# DSI_Protocol_Engine register map
Vendor: Texas Instruments
Peripheral module from a debugger description file (folder omap36xx).
Registers are 32-bit, read-write, reset 0x0 unless marked. A register's access mark holds for its fields unless they carry their own. Offsets are as the file gives them; lines under a group give offsets from that group; [hi:lo] are bit positions; {n}, {i} and the like mark numbered series; 'fields as' and 'values as' point back to an identical list; <NAME> marks a mode.

## DSI_Protocol_Engine (part 1 of 2)
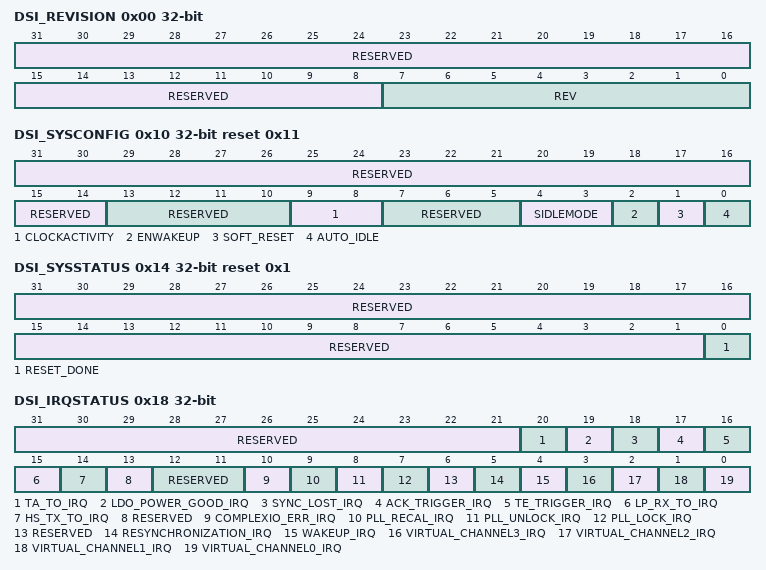
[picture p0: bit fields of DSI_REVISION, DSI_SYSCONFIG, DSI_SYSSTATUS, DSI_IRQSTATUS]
0x00 DSI_REVISION ro (reset mask 0xFFFFFF00) — MODULE REVISION This register contains the IP revision code in binary coded digital. For example, we have: 0x01 = revision 0.1 and 0x21 = revision 2.1
  [31:8] RESERVED — Write 0s for future compatibility.Reads returns 0.
  [7:0] REV — IP revision [7:4] Major revision[3:0] Minor revision
0x10 DSI_SYSCONFIG reset 0x11 — SYSTEM CONFIGURATION REGISTER This register is the system configuration register.
  [31:14] RESERVED — Write 0s for future compatibility.Reads returns 0.
  [13:10] RESERVED — Write 0s for future compatibility.
  [9:8] CLOCKACTIVITY — Clocks activity during wake up mode period
    0=Interface and Functional clocks can be switched off; 1=Functional clocks can be switched off and Interface clocks are maintained during wake up period; 2=Interface clocks can be switched off and Functional clocks are maintained during wake up period; 3=Interface and Functional clocks are maintained during wake up period
  [7:5] RESERVED — Write 0s for future compatibility.Reads returns 0.
  [4:3] SIDLEMODE — Slave interface power management, Idle req/ack control
    0=Force-idle. An idle request is acknowledged unconditionally; 1=No-idle. An idle request is never acknowledged; 2=Smart-idle. Acknowledgement to an idle request is given based on the internal activity of the module.
  [2] ENWAKEUP — Wake-up mode enable bit
    0=Wakeup is disabled; 1=Wakeup is enabled,
  [1] SOFT_RESET — Software reset. Set the bit to 1 to trigger a module reset. The bit is automatically reset by the hw. During reads return 0.
    0=Normal mode; 1=The module is reset
  [0] AUTO_IDLE — Internal interface clock gating strategy
    0=Interface clock is free-running; 1=Automatic Interface clock gating strategy is applied based on the module interface activity
0x14 DSI_SYSSTATUS ro reset 0x1 — SYSTEM STATUS REGISTER This register provides status information about the module, excluding the interrupt status register.
  [31:1] RESERVED — Reads returns 0.
  [0] RESET_DONE — Internal reset monitoring
    0=Internal module reset is on going; 1=Reset completed
0x18 DSI_IRQSTATUS access per field — INTERRUPT STATUS REGISTER - All VCs + complex I/O + PLL This register associates one bit for each VC to determine which VC has generated the interrupt. The VC should be enabled for events to be generated on that VC. If the VC is disabled, the interrupt is not generated.
  [31:21] RESERVED rw — Write 0s for future compatibility.Reads returns 0.
  [20] TA_TO_IRQ rw — Turn-around Time out.
    0=READS: Event is false.WRITES: Status bit unchanged; 1=READS: Event is true (pending).WRITES: Status bit is reset
  [19] LDO_POWER_GOOD_IRQ rw — Transition of the status signal LDOPWRGOOD from the DSI_PHY indicating a state change for the supply VDDALDODSIPLL from up to down or down to up.
    values as TA_TO_IRQ
  [18] SYNC_LOST_IRQ rw — Synchronization with Video port is lost (Video mode only)
    values as TA_TO_IRQ
  [17] ACK_TRIGGER_IRQ rw — Acknowledge Trigger
    values as TA_TO_IRQ
  [16] TE_TRIGGER_IRQ rw — Tearing Effect Trigger
    values as TA_TO_IRQ
  [15] LP_RX_TO_IRQ rw — Interrupt for Low Power Rx Time out
    values as TA_TO_IRQ
  [14] HS_TX_TO_IRQ rw — Interrupt for high-speed Tx Time out.
    values as TA_TO_IRQ
  [13] RESERVED rw — Write 0s for future compatibility.Reads returns 0.
  [12:11] RESERVED rw — Write 0s for future compatibility.Reads returns 0.
  [10] COMPLEXIO_ERR_IRQ ro — Error signaling from complex I/O: status of the complex I/O errors received from the complex I/O(events are defined inDSI_COMPLEXIO_IRQSTATUS).
    0=READS: Event is false; 1=READS: Event is true (pending)
  [9] PLL_RECAL_IRQ rw — PLL recalibration event (assertion of recalibration signal from the DSI PLL Control module)
    values as TA_TO_IRQ
  [8] PLL_UNLOCK_IRQ rw — PLL un-lock event (de-assertion of lock signal from the DSI PLL Control module)
    0=READS: Event is false.WRITES: Status bit unchanged; 1=READS: Event is true (pending). WRITES: Status bit is reset.
  [7] PLL_LOCK_IRQ rw — PLL lock event (assertion of lock signal from the DSI PLL Control module)
    values as TA_TO_IRQ
  [6] RESERVED rw — Write 0s for future compatibility.Reads returns 0.
  [5] RESYNCHRONIZATION_IRQ rw — Video mode resynchronizationIndicates that the video port works but the configuration of the timings for the display controller (DISPC) and for DSI protocol engine may have to be modified to avoid the resynchronization to occur. .
    0=READS: Event is false. WRITES: Status bit unchanged.; 1=READS: Event is true (pending). WRITES: Status bit is reset.
  [4] WAKEUP_IRQ rw — Wakeup
    values as TA_TO_IRQ
  [3] VIRTUAL_CHANNEL3_IRQ ro — Virtual channel #3Error signaling from DSI Virtual Channel3: Status of DSI Virtual Channel3 errors received from DSI Virtual Channel3 (events are defined in DSI_VC3_IRQSTATUS). .
    0=READS: Event is false; 1=READS: Event is true (pending)
  [2] VIRTUAL_CHANNEL2_IRQ ro — Virtual channel #2Error signaling from DSI Virtual Channel2: Status of DSI Virtual Channel2 errors received from DSI Virtual Channel2 (events are defined in DSI_VC2_IRQSTATUS). .
    0=READS: Event is false; 1=READS: Event is true (pending)
  [1] VIRTUAL_CHANNEL1_IRQ ro — Virtual channel #1Error signaling from DSI Virtual Channel1: Status of DSI Virtual Channel1 errors received from DSI Virtual Channel1 (events are defined in DSI_VC1_IRQSTATUS). .
    0=READS: Event is false; 1=READS: Event is true (pending)
  [0] VIRTUAL_CHANNEL0_IRQ ro — Virtual channel #0Error signaling from DSI Virtual Channel0: Status of the DSI Virtual Channel0 errors received from DSI Virtual Channel0 (events are defined in DSI_VC0_IRQSTATUS). .
    0=READS: Event is false; 1=READS: Event is true (pending)
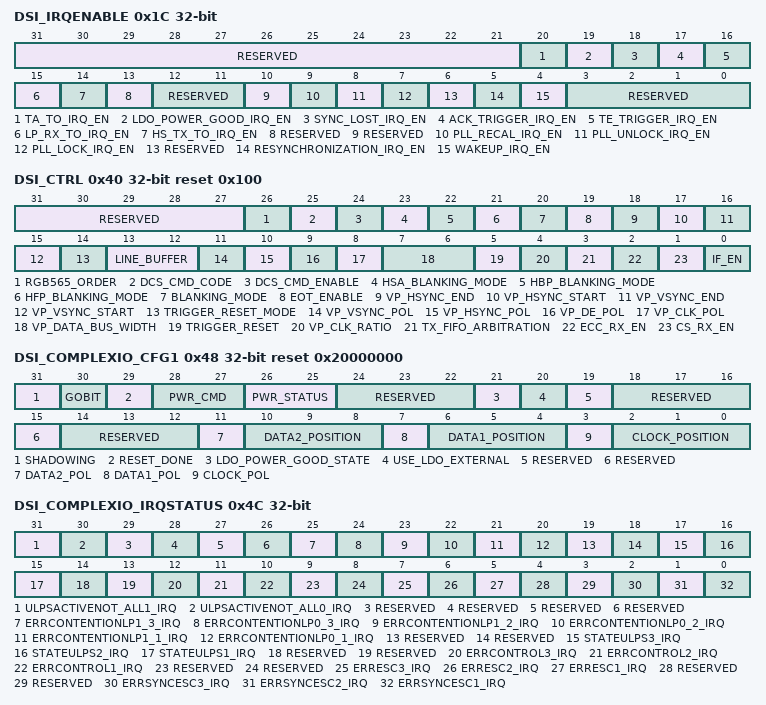
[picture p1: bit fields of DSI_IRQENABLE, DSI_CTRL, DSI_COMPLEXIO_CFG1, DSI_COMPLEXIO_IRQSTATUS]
0x1C DSI_IRQENABLE — INTERRUPT ENABLE REGISTER - This register associates one bit for each VC to enable/disable each VC individually.
  [31:21] RESERVED — Write 0s for future compatibility.Reads returns 0.
  [20] TA_TO_IRQ_EN — Turn-around Time out.
    0=Event is masked; 1=Event generates an interrupt when it occurs
  [19] LDO_POWER_GOOD_IRQ_EN — Transition of the status signal LDOPWRGOOD from the DSI_PHY indicating a state change for the supply VDDALDODSIPLL from up to down or down to up.
    values as TA_TO_IRQ_EN
  [18] SYNC_LOST_IRQ_EN — Synchronization with Video port is lost (Video mode only)
    values as TA_TO_IRQ_EN
  [17] ACK_TRIGGER_IRQ_EN — Acknowledge trigger
    values as TA_TO_IRQ_EN
  [16] TE_TRIGGER_IRQ_EN — Tearing Effect trigger
    values as TA_TO_IRQ_EN
  [15] LP_RX_TO_IRQ_EN — Interrupt for Low Power Rx Time out.
    values as TA_TO_IRQ_EN
  [14] HS_TX_TO_IRQ_EN — Interrupt for high-speed Tx Time out.
    values as TA_TO_IRQ_EN
  [13] RESERVED — Write 0s for future compatibility.Reads returns 0.
  [12:11] RESERVED — Write 0s for future compatibility.Reads returns 0.
  [10] RESERVED — Write 0s for future compatibility.Reads returns 0.
  [9] PLL_RECAL_IRQ_EN — PLL recalibration event (assertion of recalibration signal from the DSI PLL Control module)
    values as TA_TO_IRQ_EN
  [8] PLL_UNLOCK_IRQ_EN — PLL un-lock event (de-assertion of lock signal from the DSI PLL Control module)
    values as TA_TO_IRQ_EN
  [7] PLL_LOCK_IRQ_EN — PLL lock event (assertion of lock signal from the DSI PLL Control module)
    values as TA_TO_IRQ_EN
  [6] RESERVED — Write 0s for future compatibility.Reads returns 0.
  [5] RESYNCHRONIZATION_IRQ_EN — Resynchronization
    values as TA_TO_IRQ_EN
  [4] WAKEUP_IRQ_EN — Wakeup
    values as TA_TO_IRQ_EN
  [3:0] RESERVED — Write 0s for future compatibility.Reads returns 0.
0x40 DSI_CTRL reset 0x100 — GLOBAL CONTROL REGISTER This register controls the DSI Protocol Engine module. This register should not be modified dynamically (except IF_EN bit field).
  [31:27] RESERVED — Write 0s for future compatibility.Reads returns 0.
  [26] RGB565_ORDER — Byte order for RBG565 command mode from video port
    0=RGB565_ORDER_0; 1=Byte order as for video mode
  [25] DCS_CMD_CODE — DCS command code value to insert between header and video port data when enabled by DCS_CMD_ENABLE
    0=DCS write memory continue code is inserted; 1=DCS write memory start code is inserted
  [24] DCS_CMD_ENABLE — Enables automatic insertion of DCS command codes when data is sourced by the video port.
    0=DCS command code is not inserted when command mode traffic is coming from the Video Port; 1=DCS command code is inserted automatically when command mode traffic is coming from the Video Port
  [23] HSA_BLANKING_MODE — Blanking mode
    0=Packets in TX FIFO are sent during HSA blanking period of video mode or LPS is used; 1=LONG BLANKING PACKETS only are used during HSA blanking period of video mode
  [22] HBP_BLANKING_MODE — Blanking mode
    0=Packets in TX FIFO are sent during HBP blanking period of video mode or LPS is used; 1=LONG BLANKING PACKETS only are used during HBP blanking period of video mode
  [21] HFP_BLANKING_MODE — Blanking mode
    0=Packets in TX FIFO are sent during HFP blanking period of video mode or LPS is used; 1=LONG BLANKING PACKETS only are used during HFP blanking period of video mode
  [20] BLANKING_MODE
    0=LPS is used during blanking periods of video mode (except HSA, HBP, HFP defined in HSA_BLANKING_MODE, HBP_BLANKING_MODE and HFP_BLANKING_MODE bit fields respectively) when there is no command mode data in TX FIFO ready to be sent. So blanking periods can be different during the frame depending on the TX FIFO.; 1=LONG BLANKING PACKETS are used during blanking periods of video mode (except HSA, HBP, HFP defined in HSA_BLANKING_MODE, HBP_BLANKING_MODE and HFP_BLANKING_MODE bit fields respectively) regardless of the packets present in the TX FIFO ready to be sent
  [19] EOT_ENABLE — Enable EOT packets at the end of HS transmission.
    0=No EOT packets; 1=EOT packet is sent at all HS to LP transitions
  [18] VP_HSYNC_END — HSYNC end pulse.
    0=Disabled. No HSYNC END short packet is generated.; 1=Enabled. While the HSYNC END pulse is detected, the associated short packet HSYNC END is generated.
  [17] VP_HSYNC_START — HSYNC start pulse.
    0=Disabled. No HSYNC START short packet is generated.; 1=Enabled. While the HSYNC start pulse is detected, the associated short packet HSYNC START is generated.
  [16] VP_VSYNC_END — VSYNC end pulse.
    0=Disabled. No VSYNC END short packet is generated.; 1=Enabled. While the VSYNC END pulse is detected, the associated short packet VSYNC END is generated.
  [15] VP_VSYNC_START — VSYNC start pulse.
    0=Disabled. No VSYNC START short packet is generated.; 1=Enabled. While the VSYNC START pulse is detected, the associated short packet VSYNC START is generated.
  [14] TRIGGER_RESET_MODE — Selection of the trigger reset mode
    0=Synchronized: the mode is only valid if there is VC using the video mode and it is active. The principle is to wait for the current video frame to be transferred on the link. Any data received after the VSYNC are ignored.; 1=Immediate: all pending requests in TX FIFO are taken into account for transfer scheduling, the RX FIFO is ignored, and the data from video port are ignored as soon as possible. Only the current transfer on DSI link and already scheduled ones are transmitted. All the other transfers are discarded.
  [13:12] LINE_BUFFER — Number of line buffers to be used while receiving data on the video port.
    0=No line buffer; 1=1 line buffer; 2=2 line buffers
  [11] VP_VSYNC_POL — VP vertical synchronization signal polarity
    0=VSYNC signal on the video port is active low; 1=VSYNC signal on the video port is active high
  [10] VP_HSYNC_POL — VP horizontal synchronization signal polarity
    0=HSYNC signal on the video port is active low; 1=HSYNC signal on the video port is active high
  [9] VP_DE_POL — VP data enable signal polarity
    0=DE signal on the video port is active low; 1=DE signal on the video port is active high
  [8] VP_CLK_POL — VP pixel clock polarity
    0=The DSI Protocol Engine module captures the data on the VP on the pixel clock falling edge. The module connected to the VP must drive the data on the pixel clock rising edge.; 1=The DSI Protocol Engine module captures the data on the VP on the pixel clock raising edge. The module connected to the VP must drive the data on the pixel clock falling edge.
  [7:6] VP_DATA_BUS_WIDTH — Defines the size of the video port data bus
    0=16-bits data width (LSB of the 24-bit video port data bus); 1=18-bits data width (LSB of the 24-bit video port data bus); 2=24-bits data width (LSB of the 24-bit video port data bus)
  [5] TRIGGER_RESET — Send the reset trigger to the peripheral.
    0=READS: Reset trigger generation is completed. It is reset by HW when it is completed.WRITES: Cancellation of the request for Reset trigger generation (maybe too late since it is already on going); 1=READS: Generation of the reset trigger has been requested by user (could be on going but not completed yet).WRITES: Request for Reset trigger to be sent to the peripheral
  [4] VP_CLK_RATIO — This bit indicates the clock ratio between VP_CLK and VP_PCLK. The clock VP_PCLK is generated from VP_CLK. It is divided down.The information is only used when the video port is used to provide data in command mode. In the case of video mode, it is not used.
    0=The clock VP_PCLK is the clock VP_CLK divided by 2. The duty cycle of VP_PCLK is 50/50.; 1=The clock VP_PCLK is the clock VP_CLK divided by 3 or more. The duty cycle of VP_PCLK is not 50/50 for odd ratio numbers (3,5,7,...).
  [3] TX_FIFO_ARBITRATION — Defines the arbitration scheme for granting the VC pending ready requests in the TX FIFO
    0=Round-Robin Scheme is used; 1=Sequential Scheme is used
  [2] ECC_RX_EN — Enables the ECC check for the received header (short and long packets for all VC IDs).
    0=Disabled; 1=Enabled
  [1] CS_RX_EN — Enables the checksum check for the received payload (long packet only for all VC IDs).
    0=Disabled; 1=Enabled
  [0] IF_EN — Enables the module. When the module is disabled the signals from the complex I/O are gated (no updates of the interrupt status register).It is not possible to change the bit fields in the DSI_CTRL register, except IF_EN when it is enabled. All the other registers can be changed except the ones that require DSI_VCn_CTRL[0] VC_EN to be equal to 0 to be modified.
    0=The interface is disabled. If one of the VC uses the video mode with the video port to receive the data, the DSI protocol engines is disabled when the next VSYNC is received and all the data in the FIFO for the other VCs in command mode are sent to the peripherals (if BTA_EN bit is enabled, the DSI protocol engine needs to wait for the response and BTA from the peripheral before disabling all the internal logic since an acknowledge is requested).; 1=The interface is enabled immediately, the data acquisition on the video port starts on the next VSYNC (video mode) or first data received in the Slave port FIFO (command mode)
0x48 DSI_COMPLEXIO_CFG1 access per field reset 0x20000000 — COMPLEXIO CONFIGURATION REGISTER for the complex I/O This register contains the lane configuration for the order and position of the lanes (clock and data) and the polarity order for the control of the PHY differential signals in addition to the control bit for the power FSM.
  [31] SHADOWING rw — Shadowing configuration.
    0=Disabled. The writes to the DSIPHY_CFG0 and DSIPHY_CFG1 registers are done like the other SCP registers.; 1=Enabled. The writes to the DSIPHY_CFG0 and DSIPHY_CFG1 registers are done only when the GO bit is set and when the signal DISPC_UPDATE_SYNC from the display controller module is active.
  [30] GOBIT rw — Allows the synchronized update of the shadow registers when the signal DISPC_UPDATE_SYNC is active.
    0=Resets the Gobit. The hardware has finished the update of the shadow SCP registers. The bit is reset by Hardware. The software can reset the bit in case users decide to abort it. There is no guarantee that the software reset is done before the transfer of the values to the complex I/O.; 1=Set the Gobit. Only when the transfer of the new values for the two first registers is completed (2, 1, or 0 transfers are performed based on the number of registers to update), the GObit is reset. The DISPC_UPDATE_SYNC signal is used to synchronize the update. The bit must be set only when it is in reset state.
  [29] RESET_DONE ro — Internal reset monitoring of the power domain using the TxByteClkHS from the complex I/O
    0=Internal module reset is on going; 1=Reset completed
  [28:27] PWR_CMD rw — Command for power control of the complex I/O
    0=Command to change to OFF state; 1=Command to change to ON state; 2=Command to change to ultralow-power state
  [26:25] PWR_STATUS ro — Status of the power control of the complex I/O
    0=complex I/O in OFF state; 1=complex I/O in ON state; 2=complex I/O in ultralow-power state
  [24:22] RESERVED rw — Write 0s for future compatibility.Reads returns 0.
  [21] LDO_POWER_GOOD_STATE ro — Indicates the state of the signal LDOPWRGOOD. VDDALDODSIPLL: 1.2-V power supply for the PLL. The voltage is supplied by the internal or external LDO. The interrupt LDO_POWER_GOOD_IRQ is generated when a transition is detected on the signal LDOPWRGOOD from the DSI_PHY.
    0=VDDALDODSIPLL power supply is down; 1=VDDALDODSIPLL power supply is up
  [20] USE_LDO_EXTERNAL rw — Select the external LDO for the DSI_PHY.
    0=DSI_PHY internal LDO is used; 1=External LDO is used. DSI_PHY LDO is tri-stated.
  [19] RESERVED rw — Write 0s for future compatibility.Reads returns 0.
  [18:16] RESERVED rw — Write 0s for future compatibility.Reads returns 0.
  [15] RESERVED rw — Write 0s for future compatibility.Reads returns 0.
  [14:12] RESERVED rw — Write 0s for future compatibility.Reads returns 0.
  [11] DATA2_POL rw — +/- differential pin order of DATA lane 2.
    0=+/- pin order (dsi_dx=+ and dsi_dy=-); 1=-/+ pin order (dsi_dx=- and dsi_dy=+)
  [10:8] DATA2_POSITION rw — Position and order of the DATA lane 2.Other values: reserved .
    0=Not used/connected; 1=Data lane 2 is at the position 1 (line 1); 2=Data lane 2 is at the position 2 (line 2); 3=Data lane 2 is at the position 3 (line 3)
  [7] DATA1_POL rw — +/- differential pin order of DATA lane 1
    values as DATA2_POL
  [6:4] DATA1_POSITION rw — Position and order of the DATA lane 1.Other values: reserved .
    1=Data lane 1 is at the position 1 (line 1); 2=Data lane 1 is at the position 2 (line 2); 3=Data lane 1 is at the position 3 (line 3)
  [3] CLOCK_POL rw — +/- differential pin order of CLOCK lane.
    values as DATA2_POL
  [2:0] CLOCK_POSITION rw — Position and order of the CLOCK lane.The clock lane is always present.Other values: reserved .
    1=Clock lane is at the position 1 (line 1); 2=Clock lane is at the position 2 (line 2); 3=Clock lane is at the position 3 (line 3)
0x4C DSI_COMPLEXIO_IRQSTATUS — INTERRUPT STATUS REGISTER - All errors from complex I/O
  [31] ULPSACTIVENOT_ALL1_IRQ — All the ULPSActiveNOT signals corresponding to the lanes with TXULPSExit being high are high.
    values as DSI_IRQSTATUS.TA_TO_IRQ
  [30] ULPSACTIVENOT_ALL0_IRQ — All signals ULPSActiveNOT are 0
    values as DSI_IRQSTATUS.TA_TO_IRQ
  [29] RESERVED — Write 0s for future compatibility.Reads returns 0.
  [28] RESERVED — Write 0s for future compatibility.Reads returns 0.
  [27] RESERVED — Write 0s for future compatibility.Reads returns 0.
  [26] RESERVED — Write 0s for future compatibility.Reads returns 0.
  [25] ERRCONTENTIONLP1_3_IRQ — Contention LP1 error for lane #3
    values as DSI_IRQSTATUS.TA_TO_IRQ
  [24] ERRCONTENTIONLP0_3_IRQ — Contention LP0 error for lane #3
    values as DSI_IRQSTATUS.TA_TO_IRQ
  [23] ERRCONTENTIONLP1_2_IRQ — Contention LP1 error for lane #2
    values as DSI_IRQSTATUS.TA_TO_IRQ
  [22] ERRCONTENTIONLP0_2_IRQ — Contention LP0 error for lane #2
    values as DSI_IRQSTATUS.TA_TO_IRQ
  [21] ERRCONTENTIONLP1_1_IRQ — Contention LP1 error for lane #1
    values as DSI_IRQSTATUS.TA_TO_IRQ
  [20] ERRCONTENTIONLP0_1_IRQ — Contention LP0 error for lane #1
    values as DSI_IRQSTATUS.TA_TO_IRQ
  [19] RESERVED — Write 0s for future compatibility.Reads returns 0.
  [18] RESERVED — Write 0s for future compatibility.Reads returns 0.
  [17] STATEULPS3_IRQ — Lane #3 in ultralow-power state
    values as DSI_IRQSTATUS.TA_TO_IRQ
  [16] STATEULPS2_IRQ — Lane #2 in ultralow-power state
    values as DSI_IRQSTATUS.TA_TO_IRQ
  [15] STATEULPS1_IRQ — Lane #1 in ultralow-power state
    values as DSI_IRQSTATUS.TA_TO_IRQ
  [14] RESERVED — Write 0s for future compatibility.Reads returns 0.
  [13] RESERVED — Write 0s for future compatibility.Reads returns 0.
  [12] ERRCONTROL3_IRQ — Control error for lane #3
    values as DSI_IRQSTATUS.TA_TO_IRQ
  [11] ERRCONTROL2_IRQ — Control error for lane #2
    values as DSI_IRQSTATUS.TA_TO_IRQ
  [10] ERRCONTROL1_IRQ — Control error for lane #1
    values as DSI_IRQSTATUS.TA_TO_IRQ
  [9] RESERVED — Write 0s for future compatibility.Reads returns 0.
  [8] RESERVED — Write 0s for future compatibility.Reads returns 0.
  [7] ERRESC3_IRQ — Escape entry error for lane #3
    values as DSI_IRQSTATUS.TA_TO_IRQ
  [6] ERRESC2_IRQ — Escape entry error for lane #2
    values as DSI_IRQSTATUS.TA_TO_IRQ
  [5] ERRESC1_IRQ — Escape entry error for lane #1
    values as DSI_IRQSTATUS.TA_TO_IRQ
  [4] RESERVED — Write 0s for future compatibility.Reads returns 0.
  [3] RESERVED — Write 0s for future compatibility.Reads returns 0.
  [2] ERRSYNCESC3_IRQ — Low power Data transmission synchronization error for lane #3
    values as DSI_IRQSTATUS.TA_TO_IRQ
  [1] ERRSYNCESC2_IRQ — Low power Data transmission synchronization error for lane #2
    values as DSI_IRQSTATUS.TA_TO_IRQ
  [0] ERRSYNCESC1_IRQ — Low power Data transmission synchronization error for lane #1
    values as DSI_IRQSTATUS.TA_TO_IRQ
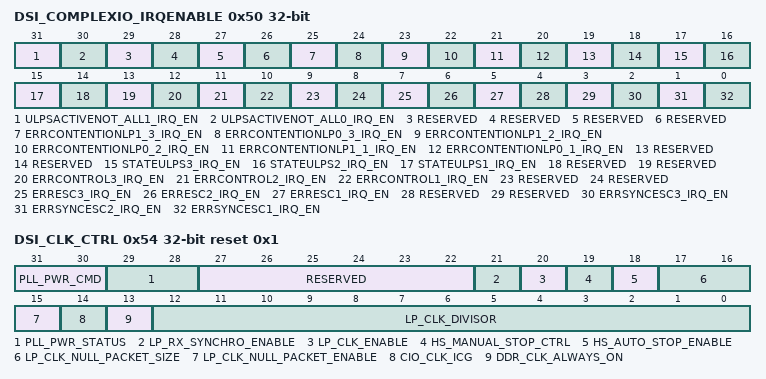
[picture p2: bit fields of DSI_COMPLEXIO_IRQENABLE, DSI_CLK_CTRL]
0x50 DSI_COMPLEXIO_IRQENABLE — INTERRUPT ENABLE REGISTER - All errors from complex I/O
  [31] ULPSACTIVENOT_ALL1_IRQ_EN — All the ULPSActiveNOT signals corresponding to the lanes with TXULPSExit being high are high.
    values as DSI_IRQENABLE.TA_TO_IRQ_EN
  [30] ULPSACTIVENOT_ALL0_IRQ_EN — All signals ULPSActiveNOT are 0
    values as DSI_IRQENABLE.TA_TO_IRQ_EN
  [29] RESERVED — Write 0s for future compatibility.Reads returns 0.
  [28] RESERVED — Write 0s for future compatibility.Reads returns 0.
  [27] RESERVED — Write 0s for future compatibility.Reads returns 0.
  [26] RESERVED — Write 0s for future compatibility.Reads returns 0.
  [25] ERRCONTENTIONLP1_3_IRQ_EN — Contention LP1 error for lane #3
    values as DSI_IRQENABLE.TA_TO_IRQ_EN
  [24] ERRCONTENTIONLP0_3_IRQ_EN — Contention LP0 error for lane #3
    values as DSI_IRQENABLE.TA_TO_IRQ_EN
  [23] ERRCONTENTIONLP1_2_IRQ_EN — Contention LP1 error for lane #2
    values as DSI_IRQENABLE.TA_TO_IRQ_EN
  [22] ERRCONTENTIONLP0_2_IRQ_EN — Contention LP0 error for lane #2
    values as DSI_IRQENABLE.TA_TO_IRQ_EN
  [21] ERRCONTENTIONLP1_1_IRQ_EN — Contention LP1 error for lane #1
    values as DSI_IRQENABLE.TA_TO_IRQ_EN
  [20] ERRCONTENTIONLP0_1_IRQ_EN — Contention LP0 error for lane #1
    values as DSI_IRQENABLE.TA_TO_IRQ_EN
  [19] RESERVED — Write 0s for future compatibility.Reads returns 0.
  [18] RESERVED — Write 0s for future compatibility.Reads returns 0.
  [17] STATEULPS3_IRQ_EN — Lane #3 in ultralow-power state
    values as DSI_IRQENABLE.TA_TO_IRQ_EN
  [16] STATEULPS2_IRQ_EN — Lane #2 in ultralow-power state
    values as DSI_IRQENABLE.TA_TO_IRQ_EN
  [15] STATEULPS1_IRQ_EN — Lane #1 in ultralow-power state
    values as DSI_IRQENABLE.TA_TO_IRQ_EN
  [14] RESERVED — Write 0s for future compatibility.Reads returns 0.
  [13] RESERVED — Write 0s for future compatibility.Reads returns 0.
  [12] ERRCONTROL3_IRQ_EN — Control error for lane #3
    values as DSI_IRQENABLE.TA_TO_IRQ_EN
  [11] ERRCONTROL2_IRQ_EN — Control error for lane #2
    values as DSI_IRQENABLE.TA_TO_IRQ_EN
  [10] ERRCONTROL1_IRQ_EN — Control error for lane #1
    values as DSI_IRQENABLE.TA_TO_IRQ_EN
  [9] RESERVED — Write 0s for future compatibility.Reads returns 0.
  [8] RESERVED — Write 0s for future compatibility.Reads returns 0.
  [7] ERRESC3_IRQ_EN — Escape entry error for lane #3
    values as DSI_IRQENABLE.TA_TO_IRQ_EN
  [6] ERRESC2_IRQ_EN — Escape entry error for lane #2
    values as DSI_IRQENABLE.TA_TO_IRQ_EN
  [5] ERRESC1_IRQ_EN — Escape entry error for lane #1
    values as DSI_IRQENABLE.TA_TO_IRQ_EN
  [4] RESERVED — Write 0s for future compatibility.Reads returns 0.
  [3] RESERVED — Write 0s for future compatibility.Reads returns 0.
  [2] ERRSYNCESC3_IRQ_EN — Low power Data transmission synchronization error for lane #3
    values as DSI_IRQENABLE.TA_TO_IRQ_EN
  [1] ERRSYNCESC2_IRQ_EN — Low power Data transmission synchronization error for lane #2
    values as DSI_IRQENABLE.TA_TO_IRQ_EN
  [0] ERRSYNCESC1_IRQ_EN — Low power Data transmission synchronization error for lane #1
    values as DSI_IRQENABLE.TA_TO_IRQ_EN
0x54 DSI_CLK_CTRL access per field reset 0x1 — CLOCK CONTROL This register controls the CLOCK GENERATION. The register can be modified only when IF_EN is reset.
  [31:30] PLL_PWR_CMD rw — Command for power control of the DSI PLL Control module
    0=Command to change to OFF state; 1=Command to change to ON state for PLL only (HSDIVISER is OFF); 2=Command to change to ON state for both PLL and HSDIVISER; 3=Command to change to ON state for both PLL and HSDIVISER (no clock output to the DSI complex I/O)
  [29:28] PLL_PWR_STATUS ro — Status of the power control of the DSI PLL Control module
    0=DSI PLL Control module in OFF state; 1=DSI PLL Control module in ON state for PLL only (HSDIVISER is OFF); 2=DSI PLL Control module in ON state for both PLL and HSDIVISER; 3=DSI PLL Control module in ON state for both PLL and HSDIVISER (no clock output to the DSI complex I/O)
  [27:22] RESERVED rw — Write 0s for future compatibility.Reads returns 0.
  [21] LP_RX_SYNCHRO_ENABLE rw — Defines if the DSI functional clock is higher or lower than 30 MHz. The information is used to define synchronization to be used for RxValidEsc.
    0=The DSI functional clock is equal or slower than 30 MHz. The synchronization is falling/rising.; 1=The DSI functional clock is higher than 30 MHz. The synchronization is rising/rising.
  [20] LP_CLK_ENABLE rw — Controls the gating of the TXCLKESC clock.
    0=Disabled. The clock is not generated. The value of LP_CLK_DIVISOR[12:0] bit field is not used and does not have to be programmed.; 1=Enabled. The clock is generated. The value of LP_CLK_DIVISOR[12:0] bit field is used and must be programmed.
  [19] HS_MANUAL_STOP_CTRL rw — In case HS_AUTO_STOP_ENABLE bit is set to 0 (reset value), the bit field allows manual control of the assertion/de-assertion of the signal DSIStopClk by users.
    0=DSIStopClk de-assertion unconditionally; 1=DSIStopClk assertion unconditionally
  [18] HS_AUTO_STOP_ENABLE rw — Enables the automatic assertion/de-assertion of DSIStopClk signal.
    0=Auto mode disabled; 1=Auto mode enabled
  [17:16] LP_CLK_NULL_PACKET_SIZE rw — Indicates the size of LP NULL Packets to be sent automatically when after the last LP packet transfer. It is used by the receiver to drain its internal pipeline. The valid values are from 0 to 3 bytes for the payload size.
  [15] LP_CLK_NULL_PACKET_ENABLE rw — Enables the generation of NULL packet in low speed.
    0=Disabled. The NULL packet is not sent in LP mode after the last LP packet.; 1=Enabled. The NULL packet is sent in LP mode after the last LP packet.
  [14] CIO_CLK_ICG rw — Controls the signal for gating the L3_ICLK clock provided to the complex I/O
    0=Disabled. The L3_ICLK clock to the DSI complex I/O is gated.; 1=Enabled. The L3_ICLK clock to the DSI complex I/O is not gated.
  [13] DDR_CLK_ALWAYS_ON rw — Defines if the DDR clock is also sent when there is no HS packets sent to the peripheral (low power mode). So TXRequest for the clock lane is not de-asserted.
    0=Disabled. The DDR clock is only provided when HS packets are sent.; 1=Enabled. The DDR clock is always sent to the peripheral regardless of the state of the data lanes (HS or LP mode).
  [12:0] LP_CLK_DIVISOR rw — Defines the ratio to be used for the generation of the low-power mode clock from DSI functional clock.The supported values are from 1 to 8191(the value 0 is invalid). The output frequency must be in the range between 20 MHz and 32 kHz.
